# LFSS_1.0 register map
Vendor: Texas Instruments
Peripheral module from a debugger description file (folder mspm33c321x).
Registers are 32-bit, read-write, no defined reset value unless marked. A register's access mark holds for its fields unless they carry their own. Offsets are as the file gives them; lines under a group give offsets from that group; [hi:lo] are bit positions; {n}, {i} and the like mark numbered series; 'fields as' and 'values as' point back to an identical list; <NAME> marks a mode.

## LFSS
0x04 LFSS_PINCM group
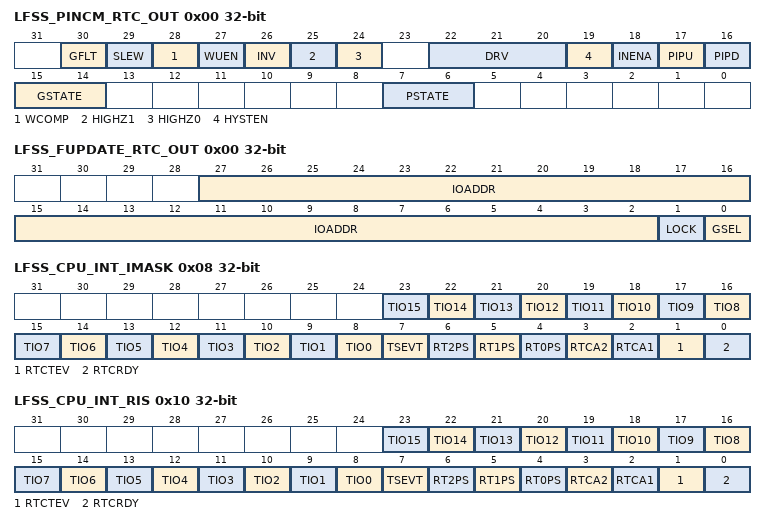
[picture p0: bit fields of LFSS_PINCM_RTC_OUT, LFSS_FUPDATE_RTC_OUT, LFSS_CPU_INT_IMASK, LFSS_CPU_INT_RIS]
  0x00 LFSS_PINCM_RTC_OUT — RTC_OUT
    [30] GFLT — Glitch Filter Enable
      0=DISABLE (No internal glitch filter); 1=ENABLE (Use internal glitch filter)
    [29] SLEW — Reserved Slew Rate Control
      0=DISABLE (No Slew Rate Control); 1=ENABLE (Use Slew Rate Control)
    [28] WCOMP — Wake up compare value
      0=MATCH_ZERO (Match 0 will wake); 1=MATCH_ONE (Match 1 will wake)
    [27] WUEN — Wake up enable
      0=NO_WAKEUP (Wake up not enabled); 1=WAKEUP (Wake up enabled)
    [26] INV — Invert digital input/output relative to peripheral/GPIO
      0=NO_CHNG (Input and output are non-inverted); 1=CHNG (Input and output are inverted)
    [25] HIGHZ1 — High-Z instead of high output
      0=DRV_HIGH (Pin can be driven high); 1=DRV_HIZ (Pin is tri-stated instead of driven high)
    [24] HIGHZ0 — High-Z instead of low output
      0=DRV_LOW (Pin can be driven low); 1=DRV_HIZ (Pin is tri-stated instead of driven low)
    [22:20] DRV — Drive strength options
      0=STRENGTH_0 (Lowest drive strength); {v}=STRENGTH_{v} (Drive strength {v+1}/8) (v=1..6); 7=STRENGTH_7 (Highest drive strength)
    [19] HYSTEN — Hysteresis enable
      0=DIS_HYST (No hysteresis); 1=EN_HYST (Hysteresis on)
    [18] INENA — Input enable
      0=INP_DISABLE (Inputs 0 to connected core); 1=INP_ENABLE (Inputs IO pad value to connected core)
    [17] PIPU — Pull up enable
      0=NO_PULL_UP; 1=PULL_UP
    [16] PIPD — Pull down enable
      0=NO_PULL_DOWN; 1=PULL_DOWN
    [15:14] GSTATE — GPIO Channel State
      0=UNASSIGNED (G-Channel is in Unassigned State); 1=HANDOVER (G-Channel is in Handover State); 2=CONC_NOT_LOCKED (G-Channel is in Connected State and not Locked (That is F field is allowed to change without going back through Unassigned state)); 3=CONC_LOCKED (G-Channel is in Connected State and Locked (That is F field is not allowed to change to a different non-Zero value until both G and P channels go to Unassigned))
    [7:6] PSTATE — Peripheral-Analog Channel State
      0=UNASSIGNED (P-Channel is in Unassigned State); 1=HANDOVER (P-Channel is in Handover State); 2=CONC_NOT_LOCKED (P-Channel is in Connected State and not Locked (That is F field is allowed to change without going back through Unassigned state)); 3=CONC_LOCKED (P-Channel is in Connected State and Locked (That is F field is not allowed to change to a different non-Zero value until both G and P channels go to Unassigned))
0x204 LFSS_FUPDATE group
  0x00 LFSS_FUPDATE_RTC_OUT — FUPDATE version of RTC_OUT
    [27:2] IOADDR — IO Address. This is the address that corresponds to the SOC address[27:2] of the module IP instance specific IO signal in the Full Write subregion of the pinmux subregion.
    [1] LOCK — Sets lock bit
      0=NOEFFECT (Writing this value has no effect); 1=LOCK (Set channel lock bit)
    [0] GSEL — GPIO channel Select 0: Select the P-Channel for the F update 1: Select the G-Channel for the F update
      0=PCHAN (Select the P-Channel for the F update); 1=GCHAN (Select the G-Channel for the F update)
0x400 LFSS_FSUB_0 — Subscriber Port 0
  [7:0] CHANID — 0 = disconnected. 1-255 = connected to channelID = CHANID.
    0=MNIMUM (0 is an allowed value, signifying that the event is unconnected); 0=UNCONNECTED (A value of 0 specifies that the event is not connected); 255=MAXIMUM (Consult your device datasheet as the actual allowed maximum may be less than 255.)
0x440 LFSS_FPUB_0 — Publisher Port 0
  [7:0] CHANID — 0 = disconnected. 1-15 = connected to channelID = CHANID.
    values as LFSS_FSUB_0.CHANID
0x480 LFSS_CPU_CONNECT_0 access not given — CPU Connect
0x1004 LFSS_CLKSEL ro — Clock Select for Ultra Low Power peripherals
  [1] LFCLK_SEL — Selects LFCLK as clock source if enabled
    0=DISABLE (LFCLK is disabled); 1=ENABLE (LFCLK is enabled)
0x1020 LFSS_CPU_INT group
  0x00 LFSS_CPU_INT_IIDX ro — Interrupt Index Register
    [7:0] STAT — Interrupt index status
      0=NO_INTR (No interrupt pending); 1=RTCRDY (RTC ready); 2=RTCTEV (RTC time event); 3=RTCA1 (RTC alarm 1); 4=RTCA2 (RTC alarm 2); 5=RT0PS (RTC prescale timer 0); 6=RT1PS (RTC prescale timer 1); 7=RT2PS (RTC prescale timer 2); 8=TSEVT (Time stamp event); {v}=TIO{v-9} (Tamper I/O {v-9} event) (v=9..24)
  0x08 LFSS_CPU_INT_IMASK — Interrupt mask
    [all] fields
      0=CLR (Clear Interrupt Mask); 1=SET (Set Interrrupt Mask)
    [n+8] TIO{n} (n=0..15) — Tamper I/O {n} event
    [7] TSEVT — Time stamp event
    [6] RT2PS — RTC prescale timer 2
    [5] RT1PS — RTC prescale timer 1
    [4] RT0PS — RTC prescale timer 0
    [3] RTCA2 — RTC alarm 2
    [2] RTCA1 — RTC alarm 1
    [1] RTCTEV — RTC time event
    [0] RTCRDY — RTC ready
  0x10 LFSS_CPU_INT_RIS — Raw interrupt status
    [all] fields
      0=CLR (Interrupt did not occur); 1=SET (Interrupt occurred)
    [n+8] TIO{n} (n=0..15) — Tamper I/O {n} event
    [7] TSEVT — Time stamp event
    [6] RT2PS — RTC prescale timer 2
    [5] RT1PS — RTC prescale timer 1
    [4] RT0PS — RTC prescale timer 0
    [3] RTCA2 — RTC alarm 2
    [2] RTCA1 — RTC alarm 1
    [1] RTCTEV — RTC time event
    [0] RTCRDY — RTC ready
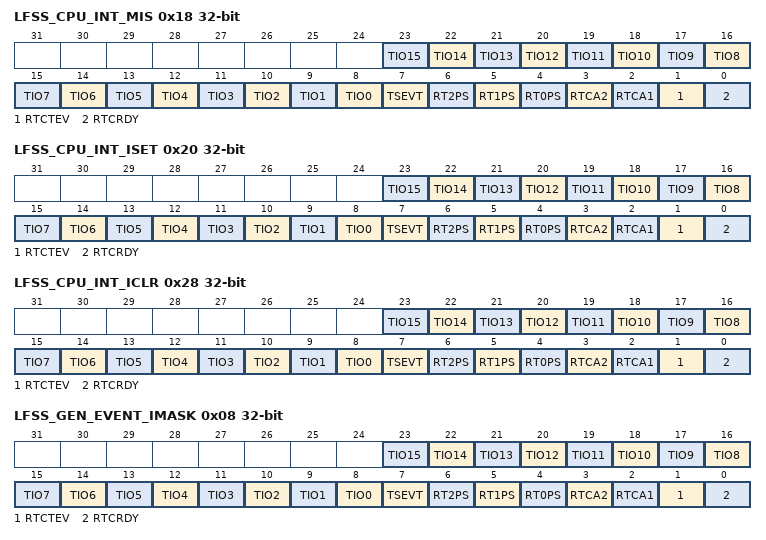
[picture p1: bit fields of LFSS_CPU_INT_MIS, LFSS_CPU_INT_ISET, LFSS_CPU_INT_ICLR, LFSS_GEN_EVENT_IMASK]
  0x18 LFSS_CPU_INT_MIS — Masked interrupt status
    [all] fields
      0=CLR (Interrupt did not occur or is masked out); 1=SET (Interrupt occurred)
    [n+8] TIO{n} (n=0..15) — Tamper I/O {n} event
    [7] TSEVT — Time stamp event
    [6] RT2PS — RTC prescale timer 2
    [5] RT1PS — RTC prescale timer 1
    [4] RT0PS — RTC prescale timer 0
    [3] RTCA2 — RTC alarm 2
    [2] RTCA1 — RTC alarm 1
    [1] RTCTEV — RTC time event
    [0] RTCRDY — RTC ready
  0x20 LFSS_CPU_INT_ISET — Interrupt set
    [all] fields
      0=NO_EFFECT (Writing 0 has no effect); 1=SET (Set interrupt)
    [n+8] TIO{n} (n=0..15) — Tamper I/O {n} event
    [7] TSEVT — Time stamp event
    [6] RT2PS — RTC prescale timer 2
    [5] RT1PS — RTC prescale timer 1
    [4] RT0PS — RTC prescale timer 0
    [3] RTCA2 — RTC alarm 2
    [2] RTCA1 — RTC alarm 1
    [1] RTCTEV — RTC time event
    [0] RTCRDY — RTC ready
  0x28 LFSS_CPU_INT_ICLR — Interrupt clear
    [all] fields
      0=NO_EFFECT (Writing 0 has no effect); 1=CLR (Clear interrupt)
    [n+8] TIO{n} (n=0..15) — Tamper I/O {n} event
    [7] TSEVT — Time stamp event
    [6] RT2PS — RTC prescale timer 2
    [5] RT1PS — RTC prescale timer 1
    [4] RT0PS — RTC prescale timer 0
    [3] RTCA2 — RTC alarm 2
    [2] RTCA1 — RTC alarm 1
    [1] RTCTEV — RTC time event
    [0] RTCRDY — RTC ready
0x1050 LFSS_GEN_EVENT group
  0x00 LFSS_GEN_EVENT_IIDX ro — Interrupt Index Register
    fields as LFSS_CPU_INT.LFSS_CPU_INT_IIDX
  0x08 LFSS_GEN_EVENT_IMASK — Interrupt mask
    fields as LFSS_CPU_INT.LFSS_CPU_INT_IMASK
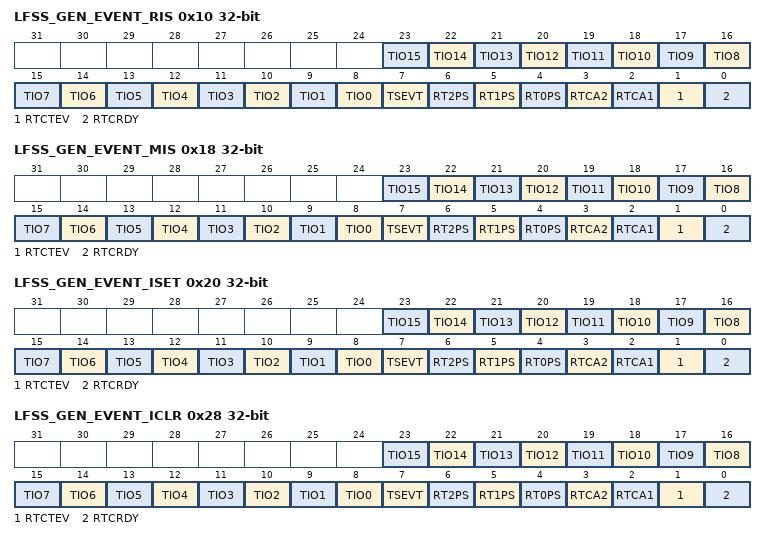
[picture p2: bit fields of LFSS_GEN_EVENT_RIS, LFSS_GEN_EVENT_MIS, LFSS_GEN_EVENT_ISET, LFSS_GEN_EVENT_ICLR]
  0x10 LFSS_GEN_EVENT_RIS — Raw interrupt status
    fields as LFSS_CPU_INT.LFSS_CPU_INT_RIS
  0x18 LFSS_GEN_EVENT_MIS — Masked interrupt status
    fields as LFSS_CPU_INT.LFSS_CPU_INT_MIS
  0x20 LFSS_GEN_EVENT_ISET — Interrupt set
    fields as LFSS_CPU_INT.LFSS_CPU_INT_ISET
  0x28 LFSS_GEN_EVENT_ICLR — Interrupt clear
    fields as LFSS_CPU_INT.LFSS_CPU_INT_ICLR
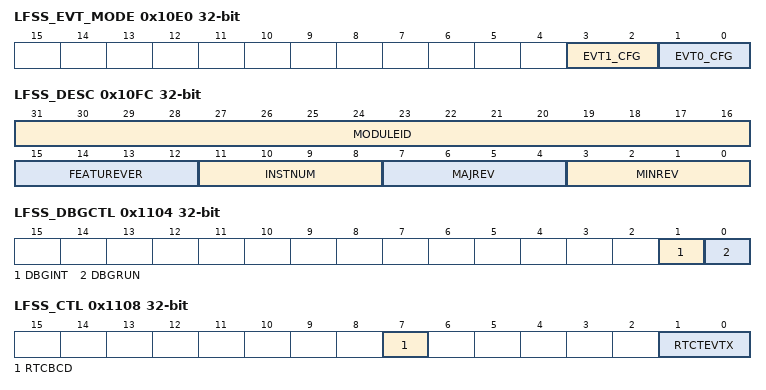
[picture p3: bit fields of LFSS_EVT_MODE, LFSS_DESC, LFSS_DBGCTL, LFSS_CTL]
0x10E0 LFSS_EVT_MODE ro — Event Mode
  [3:2] EVT1_CFG — Event line mode 1 select
    2=HARDWARE (The interrupt or event line is in hardware mode. The hardware (another module) clears automatically the associated RIS flag.)
  [1:0] EVT0_CFG — Event line mode 0 select
    1=SOFTWARE (The interrupt or event line is in software mode. The software ISR clears the associated RIS flag.)
0x10FC LFSS_DESC ro — LFSS Descriptor Register
  [31:16] MODULEID — Module identifier. This ID is unique for each module. 0x2911 = Module ID of the LFSS Module
    0=MINIMUM (Smallest value); 0xFFFF=MAXIMUM (Highest possible value)
  [15:12] FEATUREVER — Feature set of this module. Differentiates the complexity of the actually instantiated module if there are differences.
    0=MINIMUM (Smallest value); 15=MAXIMUM (Highest possible value)
  [11:8] INSTNUM — Instantiated version. Describes which instance of the module accessed.
    0=INST0 (This is the default, if there is only one instance - like for SSIM)
  [7:4] MAJREV — Major revision. This number holds the module revision and is incremented by the module developers. n = Major version (see device-specific data sheet)
    values as FEATUREVER
  [3:0] MINREV — Minor revision. This number holds the module revision and is incremented by the module developers. n = Minor module revision (see device-specific data sheet)
    values as FEATUREVER
0x1100 LFSS_CLKCTL — RTC Clock Control Register
  [31] MODCLKEN — This bit enables the supply of the 32kHz clock to the RTC. It will not power-up the 32kHz crystal oscillator this needs to be done in the Clock System Module.
    0=DISABLE (32kHz clock is not supplied to the RTC.); 1=ENABLE (32kHz clock is supplied to the RTC.)
0x1104 LFSS_DBGCTL — RTC Module Debug Control Register
  [1] DBGINT — Debug Interrupt Enable.
    0=OFF (Interrupts of the module will not be captured anymore if CPU is in debug state. Which means no update to the RTCRIS, RTCMISC and RTCIIDX register.); 1=ON (Interrupts are enabled in debug mode. Interrupt requests are signaled to the interrupt controller. If the flags are required by software (polling mode) the DGBINT bit need to be set to 1.)
  [0] DBGRUN — Debug Run.
    0=HALT (Counter is halted if CPU is in debug state.); 1=RUN (Continue to operate normally ignoring the debug state of the CPU.)
0x1108 LFSS_CTL — RTC Control Register
  [7] RTCBCD — Real-time clock BCD select. Selects BCD counting for real-time clock.
    0=BINARY (Binary code selected); 1=BCD (Binary coded decimal (BCD) code selected)
  [1:0] RTCTEVTX — Real-time clock time event 0x0 = Minute changed 0x1 = Hour changed 0x2 = Every day at midnight (00:00) 0x3 = Every day at noon (12:00)
    0=MINUTE (Generate RTC event every minute.); 1=HOUR (Generate RTC event every hour.); 2=MIDNIGHT (Generate RTC event at midnight.); 3=NOON (Generate RTC event at noon.)
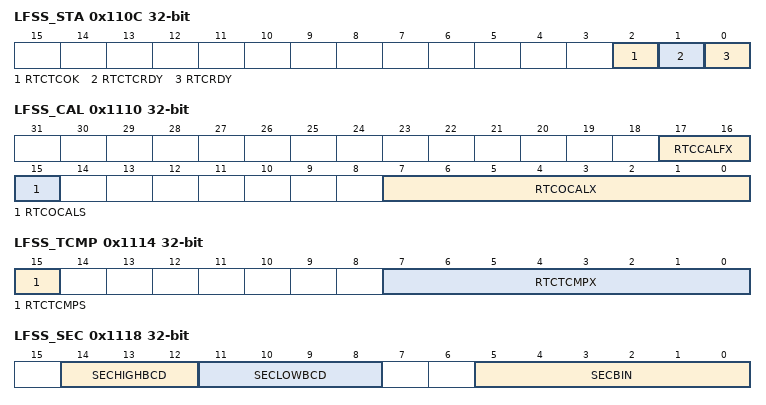
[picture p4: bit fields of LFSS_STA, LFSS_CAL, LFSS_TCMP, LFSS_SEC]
0x110C LFSS_STA ro — RTC Status Register
  [2] RTCTCOK — Real-time clock temperature compensation write OK. This is a read-only bit that indicates if the write to RTCTCMP is successful or not.
    0=NOT_OK (Write to RTCTCMPx is unsuccessful); 1=OK (Write to RTCTCMPx is successful)
  [1] RTCTCRDY — Real-time clock temperature compensation ready. This is a read only bit that indicates when the RTCTCMPx can be written. Write to RTCTCMPx should be avoided when RTCTCRDY is reset.
    0=NOT_READY (RTC temperature compensation in transition); 1=READY (RTC temperature compensation ready)
  [0] RTCRDY — Real-time clock ready. This bit indicates when the real-time clock time values are safe for reading.
    0=NOT_READY (RTC time values in transition); 1=READY (RTC time values safe for reading.)
0x1110 LFSS_CAL — RTC Clock Offset Calibration Register
  [17:16] RTCCALFX — Real-time clock calibration frequency. Selects frequency output to RTCCLK pin for calibration measurement. The corresponding port must be configured for the peripheral module function.
    0=F32KHZ (32 kHz); 1=F512HZ (512 Hz); 2=F256HZ (256 Hz); 3=F1HZ (1 Hz)
  [15] RTCOCALS — Real-time clock offset error calibration sign. This bit decides the sign of offset error calibration.
    0=DOWN (Down calibration. Frequency adjusted down.); 1=UP (Up calibration. Frequency adjusted up.)
  [7:0] RTCOCALX — Real-time clock offset error calibration. Each LSB represents approximately +1ppm (RTCOCALXS = 1) or -1ppm (RTCOCALXS = 0) adjustment in frequency. Maximum effective calibration value is +/-240ppm. Excess values written above +/-240ppm will be ignored by hardware.
    0=MINIMUM (Smallest value); 255=MAXIMUM (Highest possible value)
0x1114 LFSS_TCMP — RTC Temperature Compensation Register
  [15] RTCTCMPS — Real-time clock temperature compensation sign. This bit decides the sign of temperature compensation.
    values as LFSS_CAL.RTCOCALS
  [7:0] RTCTCMPX — Real-time clock temperature compensation. Value written into this register is used for temperature compensation of RTC. Each LSB represents approximately +1ppm (RTCTCMPS = 1) or -1ppm (RTCTCMPS = 0) adjustment in frequency. Maximum effective calibration value is +/-240ppm. Excess values written above +/-240ppm are ignored by hardware. Reading from RTCTCMP register at any time returns the cumulative value which is the signed addition of RTCOCALx and RTCTCMPX values, and the updated sign bit (RTCTCMPS) of the addition result.
    values as LFSS_CAL.RTCOCALX
0x1118 LFSS_SEC — RTC Seconds Register - Calendar Mode With Binary / BCD Format
  [14:12] SECHIGHBCD — Seconds BCD high digit (0 to 5). If RTCBCD=0 write to these bits will be ignored and read give the value 0.
    0=MINIMUM (Smallest value); 5=MAXIMUM (Highest possible value)
  [11:8] SECLOWBCD — Seconds BCD low digit (0 to 9). If RTCBCD=0 write to these bits will be ignored and read give the value 0.
    0=MINIMUM (Smallest value); 9=MAXIMUM (Highest possible value)
  [5:0] SECBIN — Seconds Binary (0 to 59). If RTCBCD=1 write to these bits will be ignored and read give the value 0.
    0=MINIMUM (Smallest value); 59=MAXIMUM (Highest possible value)
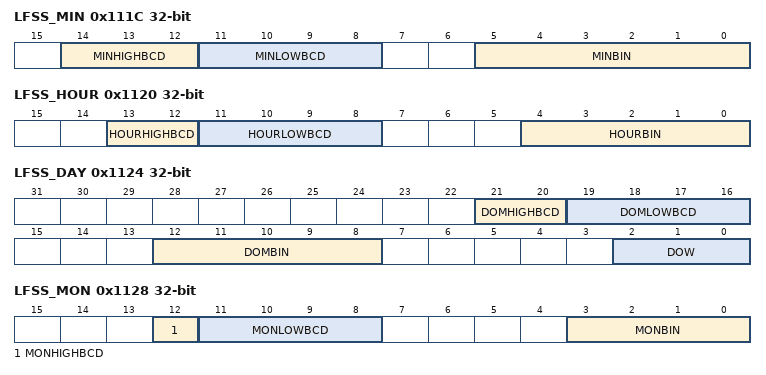
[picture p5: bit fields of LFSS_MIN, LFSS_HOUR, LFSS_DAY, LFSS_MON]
0x111C LFSS_MIN — RTC Minutes Register - Calendar Mode With Binary / BCD Format
  [14:12] MINHIGHBCD — Minutes BCD high digit (0 to 5). If RTCBCD=0 write to these bits will be ignored and read give the value 0.
    values as LFSS_SEC.SECHIGHBCD
  [11:8] MINLOWBCD — Minutes BCD low digit (0 to 9). If RTCBCD=0 write to these bits will be ignored and read give the value 0.
    values as LFSS_SEC.SECLOWBCD
  [5:0] MINBIN — Minutes Binary (0 to 59). If RTCBCD=1 write to these bits will be ignored and read give the value 0.
    values as LFSS_SEC.SECBIN
0x1120 LFSS_HOUR — RTC Hours Register - Calendar Mode With Binary / BCD Format
  [13:12] HOURHIGHBCD — Hours BCD high digit (0 to 2). If RTCBCD=0 write to these bits will be ignored and read give the value 0.
    0=MINIMUM (Smallest value); 2=MAXIMUM (Highest possible value)
  [11:8] HOURLOWBCD — Hours BCD low digit (0 to 9). If RTCBCD=0 write to these bits will be ignored and read give the value 0.
    values as LFSS_SEC.SECLOWBCD
  [4:0] HOURBIN — Hours Binary (0 to 23). If RTCBCD=1 write to these bits will be ignored and read give the value 0.
    0=MINIMUM (Smallest value); 23=MAXIMUM (Highest possible value)
0x1124 LFSS_DAY — RTC Day Of Week / Month Register - Calendar Mode With Binary / BCD Format
  [21:20] DOMHIGHBCD — Day of month BCD high digit (0 to 3). If RTCBCD=0 write to these bits will be ignored and read give the value 0.
    0=MINIMUM (Smallest value); 3=MAXIMUM (Highest possible value)
  [19:16] DOMLOWBCD — Day of month BCD low digit (0 to 9). If RTCBCD=0 write to these bits will be ignored and read give the value 0.
    values as LFSS_SEC.SECLOWBCD
  [12:8] DOMBIN — Day of month Binary (1 to 28, 29, 30, 31). If RTCBCD=1 write to these bits will be ignored and read give the value 0.
    0=MINIMUM (Smallest value); 31=MAXIMUM (Highest possible value)
  [2:0] DOW — Day of week (0 to 6). These bits are valid if RTCBCD=1 or RTCBCD=0.
    0=MINIMUM (Smallest value); 6=MAXIMUM (Highest possible value)
0x1128 LFSS_MON — RTC Month Register - Calendar Mode With Binary / BCD Format
  [12] MONHIGHBCD — Month BCD high digit (0 or 1). If RTCBCD=0 write to these bits will be ignored and read give the value 0.
    0=MINIMUM (Smallest value); 1=MAXIMUM (Highest possible value)
  [11:8] MONLOWBCD — Month BCD low digit (0 to 9). If RTCBCD=0 write to these bits will be ignored and read give the value 0.
    values as LFSS_SEC.SECLOWBCD
  [3:0] MONBIN — Month Binary (1 to 12). If RTCBCD=1 write to these bits will be ignored and read give the value 0.
    0=MINIMUM (Smallest value); 12=MAXIMUM (Highest possible value)
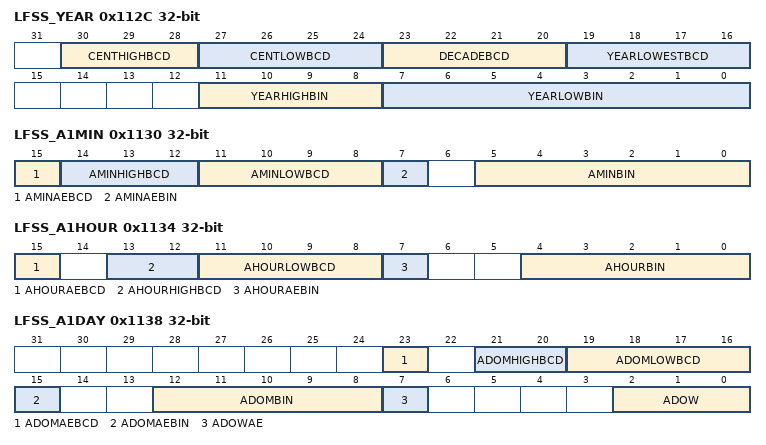
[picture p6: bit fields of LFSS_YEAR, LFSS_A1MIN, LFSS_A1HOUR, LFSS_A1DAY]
0x112C LFSS_YEAR — RTC Year Register - Calendar Mode With Binary / BCD Format
  [30:28] CENTHIGHBCD — Century BCD high digit (0 to 4). If RTCBCD=0 write to these bits will be ignored and read give the value 0.
    0=MINIMUM (Smallest value); 4=MAXIMUM (Highest possible value)
  [27:24] CENTLOWBCD — Century BCD low digit (0 to 9). If RTCBCD=0 write to these bits will be ignored and read give the value 0.
    values as LFSS_SEC.SECLOWBCD
  [23:20] DECADEBCD — Decade BCD (0 to 9). If RTCBCD=0 write to these bits will be ignored and read give the value 0.
    values as LFSS_SEC.SECLOWBCD
  [19:16] YEARLOWESTBCD — Year BCD lowest digit (0 to 9). If RTCBCD=0 write to these bits will be ignored and read give the value 0.
    values as LFSS_SEC.SECLOWBCD
  [11:8] YEARHIGHBIN — Year Binary high byte. Valid values for Year are 0 to 4095. If RTCBCD=1 write to these bits will be ignored and read give the value 0.
    values as LFSS_DESC.FEATUREVER
  [7:0] YEARLOWBIN — Year Binary low byte. Valid values for Year are 0 to 4095. If RTCBCD=1 write to these bits will be ignored and read give the value 0.
    values as LFSS_CAL.RTCOCALX
0x1130 LFSS_A1MIN — RTC Minute Alarm Register - Calendar Mode With Binary / BCD Format
  [15] AMINAEBCD — Alarm Minutes BCD enable. If RTCBCD=0 this bit is always 0. Write to this bit will be ignored. 0x0= Alarm disabled. 0x1= Alarm enabled.
    0=DISABLE (No alarm); 1=ENABLE (Alarm enabled)
  [14:12] AMINHIGHBCD — Alarm Minutes BCD high digit (0 to 5). If RTCBCD=0 write to these bits will be ignored and read give the value 0.
    values as LFSS_SEC.SECHIGHBCD
  [11:8] AMINLOWBCD — Alarm Minutes BCD low digit (0 to 9). If RTCBCD=0 write to these bits will be ignored and read give the value 0.
    values as LFSS_SEC.SECLOWBCD
  [7] AMINAEBIN — Alarm Minutes Binary enable. If RTCBCD=1 this bit is always 0. Write to this bit will be ignored. 0x0= Alarm disabled. 0x1= Alarm enabled.
    0=DISABLE (No alarm); 1=ENABLE (Alarm enabled)
  [5:0] AMINBIN — Alarm Minutes Binary (0 to 59). If RTCBCD=1 write to these bits will be ignored and read give the value 0.
    values as LFSS_SEC.SECBIN
0x1134 LFSS_A1HOUR — RTC Hours Alarm Register - Calendar Mode With Binary / BCD Format
  [15] AHOURAEBCD — Alarm Hours BCD enable. If RTCBCD=0 this bit is always 0. Write to this bit will be ignored. 0x0= Alarm disabled. 0x1= Alarm enabled.
    0=DISABLE (No alarm); 1=ENABLE (Alarm enabled)
  [13:12] AHOURHIGHBCD — Alarm Hours BCD high digit (0 to 2). If RTCBCD=0 write to these bits will be ignored and read give the value 0..
    values as LFSS_HOUR.HOURHIGHBCD
  [11:8] AHOURLOWBCD — Alarm Hours BCD low digit (0 to 9). If RTCBCD=0 write to these bits will be ignored and read give the value 0.
    values as LFSS_SEC.SECLOWBCD
  [7] AHOURAEBIN — Alarm Hours Binary enable. If RTCBCD=1 this bit is always 0. Write to this bit will be ignored. 0x0= Alarm disabled. 0x1= Alarm enabled.
    0=DISABLE (No alarm); 1=ENABLE (Alarm enabled)
  [4:0] AHOURBIN — Alarm Hours Binary (0 to 23). If RTCBCD=1 write to these bits will be ignored and read give the value 0.
    values as LFSS_HOUR.HOURBIN
0x1138 LFSS_A1DAY — RTC Alarm Day Of Week / Month Register - Calendar Mode With Binary / BCD Format
  [23] ADOMAEBCD — Alarm Day of month BCD enable. If RTCBCD=0 this bit is always 0. Write to this bit will be ignored. 0x0= Alarm disabled. 0x1= Alarm enabled.
    0=DISABLE (No alarm); 1=ENABLE (Alarm enabled)
  [21:20] ADOMHIGHBCD — Alarm Day of month BCD high digit (0 to 3). If RTCBCD=0 write to these bits will be ignored and read give the value 0.
    values as LFSS_DAY.DOMHIGHBCD
  [19:16] ADOMLOWBCD — Alarm Day of month BCD low digit (0 to 9). If RTCBCD=0 write to these bits will be ignored and read give the value 0.
    values as LFSS_SEC.SECLOWBCD
  [15] ADOMAEBIN — Alarm Day of month Binary enable. If RTCBCD=1 this bit is always 0. Write to this bit will be ignored. 0x0= Alarm disabled. 0x1= Alarm enabled.
    0=DISABLE (No alarm); 1=ENABLE (Alarm enabled)
  [12:8] ADOMBIN — Alarm Day of month Binary (1 to 28, 29, 30, 31) If RTCBCD=1 write to these bits will be ignored and read give the value 0.
    values as LFSS_DAY.DOMBIN
  [7] ADOWAE — Alarm Day of week enable. This bit are valid if RTCBCD=1 or RTCBCD=0.
    0=DISABLE (No alarm); 1=ENABLE (Alarm enabled)
  [2:0] ADOW — Alarm Day of week (0 to 6). These bits are valid if RTCBCD=1 or RTCBCD=0.
    values as LFSS_DAY.DOW
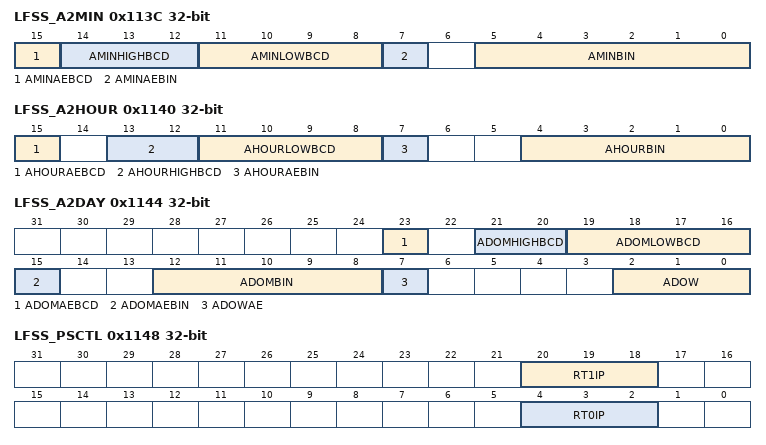
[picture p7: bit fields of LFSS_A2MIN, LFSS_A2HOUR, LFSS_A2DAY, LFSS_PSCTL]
0x113C LFSS_A2MIN — RTC Minute Alarm Register - Calendar Mode With Binary / BCD Format
  fields as LFSS_A1MIN
0x1140 LFSS_A2HOUR — RTC Hours Alarm Register - Calendar Mode With Binary / BCD Format
  fields as LFSS_A1HOUR
0x1144 LFSS_A2DAY — RTC Alarm Day Of Week / Month Register - Calendar Mode With Binary / BCD Format
  fields as LFSS_A1DAY
0x1148 LFSS_PSCTL — RTC Prescale Timer 0/1 Control Register
  [20:18] RT1IP — Prescale timer 1 interrupt interval
    0=INT15P6MS (Interval every 15.6 milisecond); 1=INT31P3MS (Interval every 31.3 milisecond); 2=INT62P5MS (Interval every 62.5 milisecond); 3=INT125MS (Interval every 125 milisecond); 4=INT250MS (Interval every 250 milisecond); 5=INT500MS (Interval every 500 milisecond); 6=INT1S (Interval every 1 second); 7=INT2S (Interval every 2 second)
  [4:2] RT0IP — Prescale timer 0 interrupt interval
    2=INT244US (Interval every 244 microsecond); 3=INT488US (Interval every 488 microsecond); 4=INT0P98MS (Interval every 0.98 milisecond); 5=INT1P95MS (Interval every 1.95 milisecond); 6=INT3P91MS (Interval every 3.91 milisecond); 7=INT7P81MS (Interval every 7.81 milisecond)
0x114C LFSS_EXTPSCTL — RTC Prescale Timer 2 Control Register
  [3:2] RT2PS — Prescale timer 2 interrupt interval
    0=INT4S (Interval every 4 second); 1=INT8S (Interval every 8 second); 2=INT16S (Interval every 16 second)
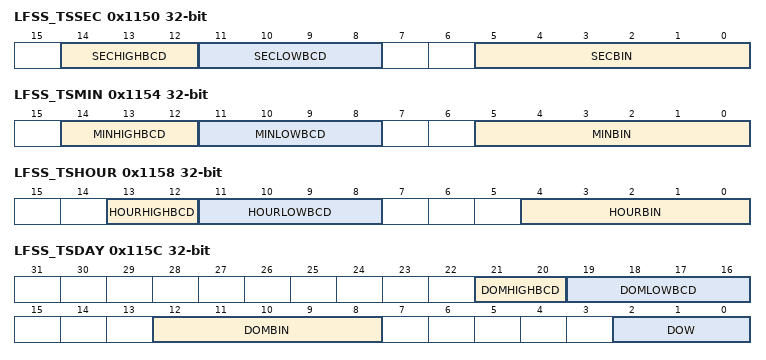
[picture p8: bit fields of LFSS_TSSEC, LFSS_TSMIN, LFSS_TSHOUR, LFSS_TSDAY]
0x1150 LFSS_TSSEC — Time Stamp Seconds Register - Calendar Mode With Binary / BCD Format
  [14:12] SECHIGHBCD — Time Stamp Seconds BCD high digit (0 to 5). If RTCBCD=0 write to these bits will be ignored and read give the value 0.
    values as LFSS_SEC.SECHIGHBCD
  [11:8] SECLOWBCD — Time Stamp Seconds BCD low digit (0 to 9). If RTCBCD=0 write to these bits will be ignored and read give the value 0.
    values as LFSS_SEC.SECLOWBCD
  [5:0] SECBIN — Time Stamp Second Binary (0 to 59). If RTCBCD=1 write to these bits will be ignored and read give the value 0.
    values as LFSS_SEC.SECBIN
0x1154 LFSS_TSMIN ro — Time Stamp Minutes Register - Calendar Mode With Binary / BCD Format
  [14:12] MINHIGHBCD — Time Stamp Minutes BCD high digit (0 to 5). If RTCBCD=0 write to these bits will be ignored and read give the value 0.
    values as LFSS_SEC.SECHIGHBCD
  [11:8] MINLOWBCD — Time Stamp Minutes BCD low digit (0 to 9). If RTCBCD=0 write to these bits will be ignored and read give the value 0.
    values as LFSS_SEC.SECLOWBCD
  [5:0] MINBIN — Time Stamp Minutes Binary (0 to 59). If RTCBCD=1 write to these bits will be ignored and read give the value 0.
    values as LFSS_SEC.SECBIN
0x1158 LFSS_TSHOUR ro — Time Stamp Hours Register - Calendar Mode With Binary / BCD Format
  [13:12] HOURHIGHBCD — Time Stamp Hours BCD high digit (0 to 2). If RTCBCD=0 write to these bits will be ignored and read give the value 0.
    values as LFSS_HOUR.HOURHIGHBCD
  [11:8] HOURLOWBCD — Time Stamp Hours BCD low digit (0 to 9). If RTCBCD=0 write to these bits will be ignored and read give the value 0.
    values as LFSS_SEC.SECLOWBCD
  [4:0] HOURBIN — Time Stamp Hours Binary (0 to 23). If RTCBCD=1 write to these bits will be ignored and read give the value 0.
    values as LFSS_HOUR.HOURBIN
0x115C LFSS_TSDAY ro — Time Stamp Day Of Week / MonthRegister - Calendar Mode With Binary / BCD Format
  [21:20] DOMHIGHBCD — Time Stamp Day of month BCD high digit (0 to 3). If RTCBCD=0 write to these bits will be ignored and read give the value 0.
    values as LFSS_DAY.DOMHIGHBCD
  [19:16] DOMLOWBCD — Time Stamp Day of month BCD low digit (0 to 9). If RTCBCD=0 write to these bits will be ignored and read give the value 0.
    values as LFSS_SEC.SECLOWBCD
  [12:8] DOMBIN — Time Stamp Day of month Binary (1 to 28, 29, 30, 31) If RTCBCD=1 write to these bits will be ignored and read give the value 0.
    values as LFSS_DAY.DOMBIN
  [2:0] DOW — Time Stamp Day of week (0 to 6). These bits are valid if RTCBCD=1 or RTCBCD=0.
    values as LFSS_DAY.DOW
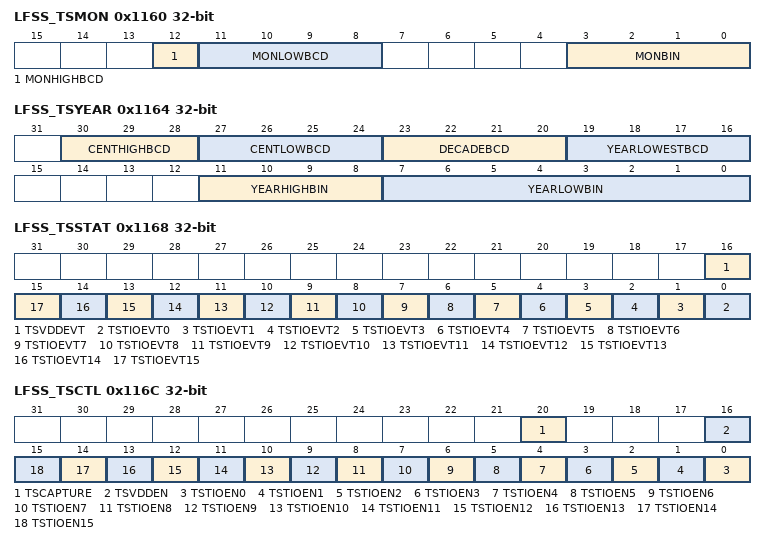
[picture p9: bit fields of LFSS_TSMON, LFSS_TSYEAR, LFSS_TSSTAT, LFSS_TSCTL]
0x1160 LFSS_TSMON ro — Time Stamp Month Register - Calendar Mode With Binary / BCD Format
  [12] MONHIGHBCD — Time Stamp Month BCD high digit (0 or 1). If RTCBCD=0 write to these bits will be ignored and read give the value 0.
    values as LFSS_MON.MONHIGHBCD
  [11:8] MONLOWBCD — Time Stamp Month BCD low digit (0 to 9). If RTCBCD=0 write to these bits will be ignored and read give the value 0.
    values as LFSS_SEC.SECLOWBCD
  [3:0] MONBIN — Time Stamp Month Binary (1 to 12). If RTCBCD=1 write to these bits will be ignored and read give the value 0.
    values as LFSS_MON.MONBIN
0x1164 LFSS_TSYEAR ro — Time Stamp Years Register - Calendar Mode With Binary / BCD Format
  [30:28] CENTHIGHBCD — Time Stamp Century BCD high digit (0 to 4). If RTCBCD=0 write to these bits will be ignored and read give the value 0.
    values as LFSS_YEAR.CENTHIGHBCD
  [27:24] CENTLOWBCD — Time Stamp Century BCD low digit (0 to 9). If RTCBCD=0 write to these bits will be ignored and read give the value 0.
    values as LFSS_SEC.SECLOWBCD
  [23:20] DECADEBCD — Time Stamp Decade BCD (0 to 9). If RTCBCD=0 write to these bits will be ignored and read give the value 0.
    values as LFSS_SEC.SECLOWBCD
  [19:16] YEARLOWESTBCD — Time Stamp Year BCD lowest digit (0 to 9). If RTCBCD=0 write to these bits will be ignored and read give the value 0.
    values as LFSS_SEC.SECLOWBCD
  [11:8] YEARHIGHBIN — Time Stamp Year Binary high byte. Valid values for Year are 0 to 4095. If RTCBCD=1 write to these bits will be ignored and read give the value 0.
    values as LFSS_DESC.FEATUREVER
  [7:0] YEARLOWBIN — Time Stamp Year Binary low byte. Valid values for Year are 0 to 4095. If RTCBCD=1 write to these bits will be ignored and read give the value 0.
    values as LFSS_CAL.RTCOCALX
0x1168 LFSS_TSSTAT ro — Time Stamp Status Register
  [all] fields
    0=CLR (no event detected); 1=SET (event detected)
  [16] TSVDDEVT — Loss of VDD caused time stamp event
  [n] TSTIOEVT{n} (n=0..15) — Tamper I/O {n} caused time stamp event
0x116C LFSS_TSCTL — Time Stamp Control Register
  [20] TSCAPTURE — Defines the capture method of the RTC timestamp when a time stamp event occurens.
    0=FIRST (Time stamp holds RTC capture at first occurrence of time stamp event.); 1=LAST (Time stamp holds RTC capture at last occurrence of time stamp event.)
  [16] TSVDDEN — Time Stamp by VDD Loss detection enable
    0=DISABLE (function disabled); 1=ENABLE (function enabled)
  [n] TSTIOEN{n} (n=0..15) — Time Stamp by Tamper I/O {n} enable
    0=DISABLE (function disabled); 1=ENABLE (function enabled)
0x1170 LFSS_TSCLR — Time Stamp Clear Register
  [0] CLR — Clear time stamp and status register.
    0=NO_EFFECT (Writing 0 has no effect); 1=CLR (clear time stamp event)
0x11F0 LFSS_LFSSRST — Low frequency sub-system reset request
  [0] VBATPOR — If set, the register bit will request a power on reset to the PMU of the LFSS.
    0=NO_EFFECT (Writing this value has no effect.); 1=SET (Request power on reset to the LFSS.)
0x11FC LFSS_RTCLOCK — Real time clock lock register
  [0] PROTECT — If set, the register bit will protect the CLKCTL, SEC, MIN, HOUR, DAY, MON, YEAR and LFSSRST from accidental writes.
    0=CLR (RTC counter is writable.); 1=SET (RTC counter is read only access.)
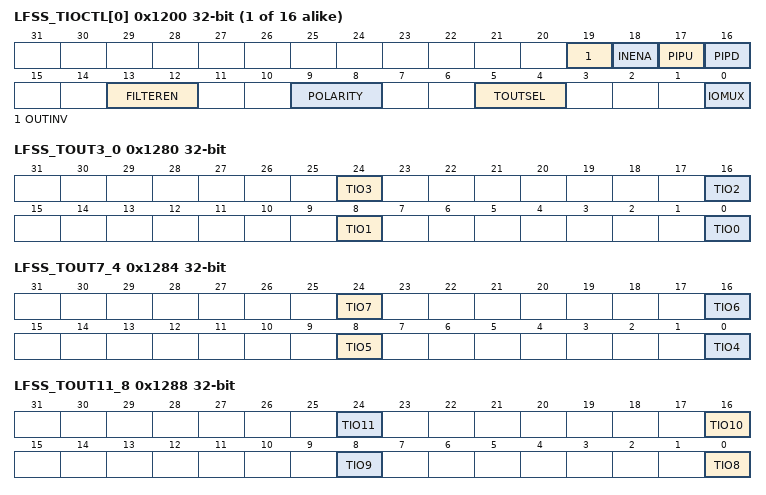
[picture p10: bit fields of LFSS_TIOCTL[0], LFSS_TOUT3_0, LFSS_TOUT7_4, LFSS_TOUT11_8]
{0x1200+4i} LFSS_TIOCTL[{i}] (i=0..15) — Tamper I/O Control Register
  [19] OUTINV — Output inversion enable
    0=DISBALE (The output inversion is disabled.); 1=ENABLE (The output inversion is enabled.)
  [18] INENA — input enable
    0=DISABLE (The input path is disabled.); 1=ENABLE (The input path is enabled.)
  [17] PIPU — pull up enable
    0=DISABLE (The pull-up function is disabled.); 1=ENABLE (The pull-up function is enabled.)
  [16] PIPD — pull down enable
    0=DISABLE (The pull-down function is disabled.); 1=ENABLE (The pull-down function is enabled.)
  [13:12] FILTEREN — Programmable counter length of digital glitch filter for TIO0
    0=NO_FLT (no filter on the tamper I/O beyond CDC synchronization sample); 1=FLT_1 (1 FLCLK minimum sample (30us)); 2=FLT_2 (3 LFCLK minimum sample (100us)); 3=FLT_3 (6 LFCLK minimum sample (200us))
  [9:8] POLARITY — Enables and configures edge detection polarity for TIO
    0=DISABLE (Edge detection disabled); 1=RISE (Detects rising edge of input event); 2=FALL (Detects falling edge of input event); 3=BOTH (Detects both rising and falling edge of input event)
  [5:4] TOUTSEL — Selects the source for TOUT control
    0=TOUT (The TOUT register is the source for TOUT); 1=LFCLKEXT (The LFCLK is the source for TOUT); 2=HEARTBEAT (The heart beat generatore is the source for TOUT); 3=TSEVTSTAT (The time stamp event status is the source for TOUT)
  [0] IOMUX — tamper I/O is controlled by SoC IOMUX module
    0=IOMUX (The tamper I/O is controlled by the IOMUX of the SoC and does allow assignment to a peripheral function. In the case the main supply (VDD) is lost, this I/O will go into a Hi-Z state.); 1=TAMPER (The tamper I/O is controlled by the TIOCTL register and stays functional during loss of the main supply (VDD).)
0x1280 LFSS_TOUT3_0 — Tamper Output 3 to 0
  [all] fields
    0=ZERO (Output is set to 0); 1=ONE (Output is set to 1)
  [24] TIO3 — This bit sets the value of the pin tamper I/O 3 (TIO3) when the output is enabled through TOE3 register.
  [16] TIO2 — This bit sets the value of the pin tamper I/O 2 (TIO0) when the output is enabled through TOE2 register.
  [8] TIO1 — This bit sets the value of the pin tamper I/O 1 (TIO1) when the output is enabled through TOE1 register.
  [0] TIO0 — This bit sets the value of the pin tamper I/O 0 (TIO0) when the output is enabled through TOE0 register.
0x1284 LFSS_TOUT7_4 — Tamper Output 7 to 4
  [all] fields
    0=ZERO (Output is set to 0); 1=ONE (Output is set to 1)
  [24] TIO7 — This bit sets the value of the pin tamper I/O 7 (TIO7) when the output is enabled through TOE7 register.
  [16] TIO6 — This bit sets the value of the pin tamper I/O 2 (TIO6) when the output is enabled through TOE6 register.
  [8] TIO5 — This bit sets the value of the pin tamper I/O 5 (TIO5) when the output is enabled through TOE5 register.
  [0] TIO4 — This bit sets the value of the pin tamper I/O 4 (TIO4) when the output is enabled through TOE4 register.
0x1288 LFSS_TOUT11_8 — Tamper Output 11 to 8
  [all] fields
    0=ZERO (Output is set to 0); 1=ONE (Output is set to 1)
  [8n-64] TIO{n} (n=8..11) — This bit sets the value of the pin tamper I/O {n} (TIO{n}) when the output is enabled through TOE{n} register.
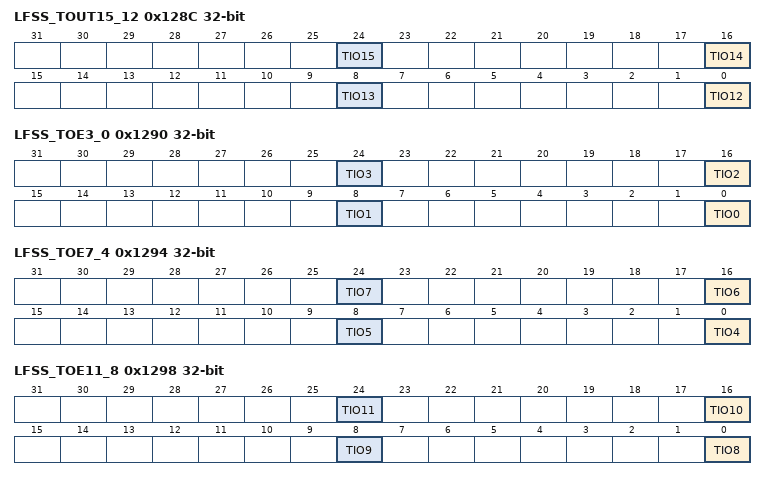
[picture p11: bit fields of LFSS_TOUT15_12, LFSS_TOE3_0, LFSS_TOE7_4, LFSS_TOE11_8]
0x128C LFSS_TOUT15_12 — Tamper Output 15 to 12
  [all] fields
    0=ZERO (Output is set to 0); 1=ONE (Output is set to 1)
  [8n-96] TIO{n} (n=12..15) — This bit sets the value of the pin tamper I/O {n} (TIO{n}) when the output is enabled through TOE{n} register.
0x1290 LFSS_TOE3_0 — Tamper Output Enable 3 to 0
  [all] fields
    0=DISABLE (output disabled); 1=ENABLE (output enabled)
  [8n] TIO{n} (n=0..3) — Enables data output for tamper I/O {n}
0x1294 LFSS_TOE7_4 — Tamper Output Enable 7 to 4
  [all] fields
    0=DISABLE (output disabled); 1=ENABLE (output enabled)
  [8n-32] TIO{n} (n=4..7) — Enables data output for tamper I/O {n}
0x1298 LFSS_TOE11_8 — Tamper Output Enable 7 to 4
  [all] fields
    0=DISABLE (output disabled); 1=ENABLE (output enabled)
  [8n-64] TIO{n} (n=8..11) — Enables data output for tamper I/O {n}
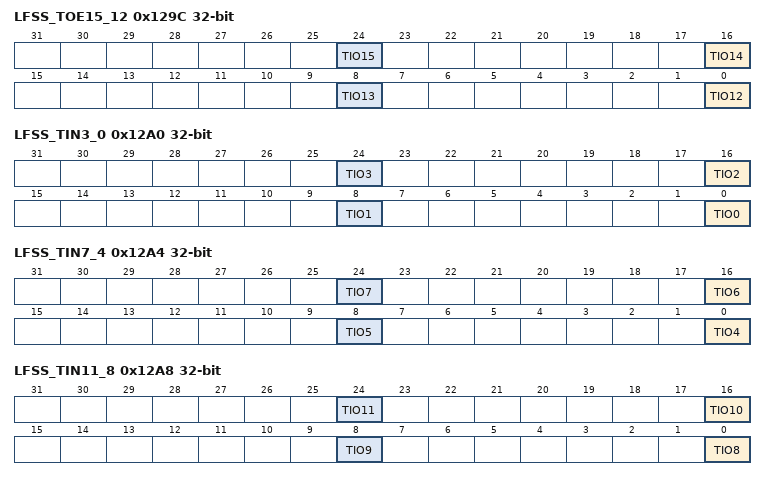
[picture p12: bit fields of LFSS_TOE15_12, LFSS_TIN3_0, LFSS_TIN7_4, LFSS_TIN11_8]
0x129C LFSS_TOE15_12 — Tamper Output Enable 7 to 4
  [all] fields
    0=DISABLE (output disabled); 1=ENABLE (output enabled)
  [8n-96] TIO{n} (n=12..15) — Enables data output for tamper I/O {n}
0x12A0 LFSS_TIN3_0 — Tamper Input Register
  [all] fields
    0=ZERO (Input value is 0); 1=ONE (Input value is 1)
  [8n] TIO{n} (n=0..3) — This bit reads the data input value of tamper I/O {n}.
0x12A4 LFSS_TIN7_4 — Tamper Input Register
  [all] fields
    0=ZERO (Input value is 0); 1=ONE (Input value is 1)
  [8n-32] TIO{n} (n=4..7) — This bit reads the data input value of tamper I/O {n}.
0x12A8 LFSS_TIN11_8 — Tamper Input Register
  [all] fields
    0=ZERO (Input value is 0); 1=ONE (Input value is 1)
  [8n-64] TIO{n} (n=8..11) — This bit reads the data input value of tamper I/O {n}.
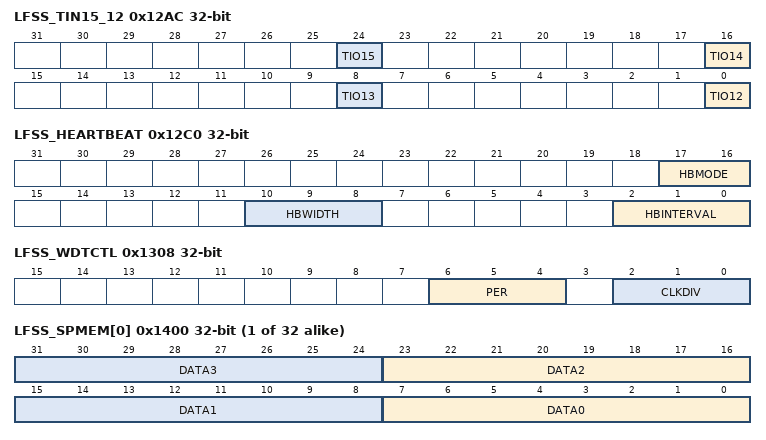
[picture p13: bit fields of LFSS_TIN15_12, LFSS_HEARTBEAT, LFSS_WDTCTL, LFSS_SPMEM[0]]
0x12AC LFSS_TIN15_12 — Tamper Input Register
  [all] fields
    0=ZERO (Input value is 0); 1=ONE (Input value is 1)
  [8n-96] TIO{n} (n=12..15) — This bit reads the data input value of tamper I/O {n}.
0x12C0 LFSS_HEARTBEAT — Heartbeat Register
  [17:16] HBMODE — Heart beat mode
    0=HB_DIS (Heart beat disabled); 1=HB_ALLWAYS (Heart beat allways enabled); 2=HB_TS (Heart beat enabled when time stamp event detected); 3=HB_VDDFAIL (Heart beat when VDD has fail condition)
  [10:8] HBWIDTH — Heart beat interval width
    0=HBPWDTH1 (Heart beat pulse width 1 msec); 1=HBPWDTH2 (Heart beat pulse width 2 msec); 2=HBPWDTH4 (Heart beat pulse width 4 msec); 3=HBPWDTH8 (Heart beat pulse width 8 msec); 4=HBPWDTH16 (Heart beat pulse width 16 msec); 5=HBPWDTH32 (Heart beat pulse width 32 msec); 6=HBPWDTH64 (Heart beat pulse width 64 msec); 7=HBPWDTH128 (Heart beat pulse width 128 msec)
  [2:0] HBINTERVAL — Heart beat interval
    0=HBINT0P125 (Heart beat interval 0.125 sec); 1=HBINT0P25 (Heart beat interval 0.25 sec); 2=HBINT0P5 (Heart beat interval 0.5 sec); 3=HBINT1 (Heart beat interval 1 sec); 4=HBINT2 (Heart beat interval 2 sec); 5=HBINT4 (Heart beat interval 4 sec); 6=HBINT8 (Heart beat interval 8 sec); 7=HBINT16 (Heart beat interval 16 sec)
0x12FC LFSS_TIOLOCK — Tamper I/O lock register
  [0] PROTECT — If set, the register bit will protect the TIOCTL and HEARTBEAT from accidental writes.
    0=CLR (Tamper I/O control is writable.); 1=SET (Tamper I/O control is read only access.)
0x1300 LFSS_WDTEN — Watchdog Timer Enable Register
  [0] ENABLE — Enable bit for the WDT.
    0=CLR (Disable WDT); 1=SET (Enable WDT)
0x1304 LFSS_WDTDBGCTL — Watchdog Timer Debug Control Register
  [0] FREE — Free run control
    0=STOP (The WDT freezes functionality while the CPU is Halted during debug and resumes when the CPU is active.); 1=RUN (The WDT ignores the state of the CPU Halted debug state.)
0x1308 LFSS_WDTCTL — Watchdog Timer Control Register
  [6:4] PER — Timer Period of the WDT. These bits select the total watchdog timer count.
    0=PER_EN_25 (Total timer count is 2^25); 1=PER_EN_21 (Total timer count is 2^21); 2=PER_EN_18 (Total timer count is 2^18); 3=PER_EN_15 (Total timer count is 2^15); 4=PER_EN_12 (Total timer count is 2^12 (default)); 5=PER_EN_10 (Total timer count is 2^10); 6=PER_EN_8 (Total timer count is 2^8); 7=PER_EN_6 (Total timer count is 2^6)
  [2:0] CLKDIV — Module Clock Divider, Divide the clock source by CLKDIV+1. Divider values from /1 to /8 are possible.
    0=MIN (Minimum value); 7=MAX (Maximum value)
0x130C LFSS_WDTCNTRST — Watchdog Timer Counter Reset Register
  [31:0] RESTART — Writing 03A7h to this register restarts the WDT Counter. Writing any other value causes a POR level reset. Read as 0x0h.
    0=MINIMUM (Minimum value); 0x3A7=VALUE (VALUE to restart the WDT counter); 0xFFFFFFFF=MAXIMUM (Maximum value)
0x1310 LFSS_WDTSTAT ro — Watchdog Timer Status Register
  [0] RUN — Watchdog running status flag.
    0=STOP (Watchdog counter stopped.); 1=RUN (Watchdog running.)
0x13FC LFSS_WDTLOCK — Watchdog timer lock register
  [0] PROTECT — If set, the register bit will protect the WDTEN and WDTCTL from accidental writes.
    0=CLR (Watchdog timer control is writable.); 1=SET (Watchdog timer control is read only access.)
{0x1400+4i} LFSS_SPMEM[{i}] (i=0..31) — Scratch Pad Memory Data Register
  [all] fields
    values as LFSS_CAL.RTCOCALX
  [8n+7:8n] DATA{n} (n=0..3) — memory data byte {n}
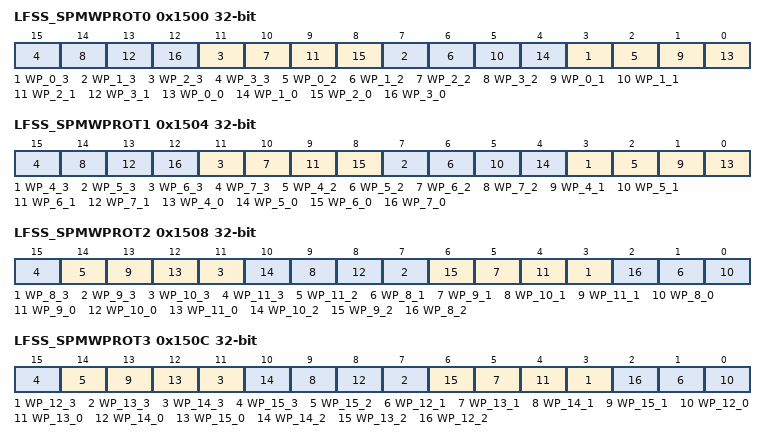
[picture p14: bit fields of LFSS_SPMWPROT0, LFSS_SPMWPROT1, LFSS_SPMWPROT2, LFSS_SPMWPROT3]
0x1500 LFSS_SPMWPROT0 — Scratch Pad Memory Write Protect Register 0
  [all] fields
    0=READWRITE (SPMEM is read and write access); 1=READONLY (SPMEM is read only access)
  [4n+3] WP_{n}_3 (n=0..3) — write protect SPMEM{n} - DATA3
  [4n+2] WP_{n}_2 (n=0..3) — write protect SPMEM{n} - DATA2
  [4n+1] WP_{n}_1 (n=0..3) — write protect SPMEM{n} - DATA1
  [4n] WP_{n}_0 (n=0..3) — write protect SPMEM{n} - DATA0
0x1504 LFSS_SPMWPROT1 — Scratch Pad Memory Write Protect Register 1
  [all] fields
    values as the fields of LFSS_SPMWPROT0
  [4n-13] WP_{n}_3 (n=4..7) — write protect SPMEM{n} - DATA3
  [4n-14] WP_{n}_2 (n=4..7) — write protect SPMEM{n} - DATA2
  [4n-15] WP_{n}_1 (n=4..7) — write protect SPMEM{n} - DATA1
  [4n-16] WP_{n}_0 (n=4..7) — write protect SPMEM{n} - DATA0
0x1508 LFSS_SPMWPROT2 — Scratch Pad Memory Write Protect Register 2
  [all] fields
    values as the fields of LFSS_SPMWPROT0
  [4n-29] WP_{n}_3 (n=8..11) — write protect SPMEM{n} - DATA3
  [14] WP_11_2 — write protect SPMEM11 - DATA2
  [4n-31] WP_{n}_1 (n=8..11) — write protect SPMEM{n} - DATA1
  [4n-32] WP_{n}_0 (n=8..11) — write protect SPMEM{n} - DATA0
  [10] WP_10_2 — write protect SPMEM610- DATA2
  [6] WP_9_2 — write protect SPMEM9 - DATA2
  [2] WP_8_2 — write protect SPMEM8 - DATA2
0x150C LFSS_SPMWPROT3 — Scratch Pad Memory Write Protect Register 3
  [all] fields
    values as the fields of LFSS_SPMWPROT0
  [4n-45] WP_{n}_3 (n=12..15) — write protect SPMEM{n} - DATA3
  [14] WP_15_2 — write protect SPMEM15 - DATA2
  [4n-47] WP_{n}_1 (n=12..15) — write protect SPMEM{n} - DATA1
  [4n-48] WP_{n}_0 (n=12..15) — write protect SPMEM{n} - DATA0
  [10] WP_14_2 — write protect SPMEM14- DATA2
  [6] WP_13_2 — write protect SPMEM13 - DATA2
  [2] WP_12_2 — write protect SPMEM12 - DATA2
0x1510 LFSS_SPMWPROT4 — Scratch Pad Memory Write Protect Register 4
  [all] fields
    values as the fields of LFSS_SPMWPROT0
  [4n-61] WP_{n}_3 (n=16..19) — write protect SPMEM{n} - DATA3
  [14] WP_19_2 — write protect SPMEM19 - DATA2
  [4n-63] WP_{n}_1 (n=16..19) — write protect SPMEM{n} - DATA1
  [4n-64] WP_{n}_0 (n=16..19) — write protect SPMEM{n} - DATA0
  [10] WP_18_2 — write protect SPMEM18- DATA2
  [6] WP_17_2 — write protect SPMEM17 - DATA2
  [2] WP_16_2 — write protect SPMEM16 - DATA2
0x1514 LFSS_SPMWPROT5 — Scratch Pad Memory Write Protect Register 5
  [all] fields
    values as the fields of LFSS_SPMWPROT0
  [4n-77] WP_{n}_3 (n=20..23) — write protect SPMEM{n} - DATA3
  [14] WP_23_2 — write protect SPMEM23 - DATA2
  [4n-79] WP_{n}_1 (n=20..23) — write protect SPMEM{n} - DATA1
  [4n-80] WP_{n}_0 (n=20..23) — write protect SPMEM{n} - DATA0
  [10] WP_22_2 — write protect SPMEM22- DATA2
  [6] WP_21_2 — write protect SPMEM21 - DATA2
  [2] WP_20_2 — write protect SPMEM20 - DATA2
0x1518 LFSS_SPMWPROT6 — Scratch Pad Memory Write Protect Register 6
  [all] fields
    values as the fields of LFSS_SPMWPROT0
  [4n-93] WP_{n}_3 (n=24..27) — write protect SPMEM{n} - DATA3
  [14] WP_27_2 — write protect SPMEM27 - DATA2
  [4n-95] WP_{n}_1 (n=24..27) — write protect SPMEM{n} - DATA1
  [4n-96] WP_{n}_0 (n=24..27) — write protect SPMEM{n} - DATA0
  [10] WP_26_2 — write protect SPMEM26- DATA2
  [6] WP_25_2 — write protect SPMEM25 - DATA2
  [2] WP_24_2 — write protect SPMEM24 - DATA2
0x151C LFSS_SPMWPROT7 — Scratch Pad Memory Write Protect Register 7
  [all] fields
    values as the fields of LFSS_SPMWPROT0
  [4n-109] WP_{n}_3 (n=28..31) — write protect SPMEM{n} - DATA3
  [14] WP_31_2 — write protect SPMEM31 - DATA2
  [4n-111] WP_{n}_1 (n=28..31) — write protect SPMEM{n} - DATA1
  [4n-112] WP_{n}_0 (n=28..31) — write protect SPMEM{n} - DATA0
  [10] WP_30_2 — write protect SPMEM30- DATA2
  [6] WP_29_2 — write protect SPMEM29 - DATA2
  [2] WP_28_2 — write protect SPMEM28 - DATA2
0x1540 LFSS_SPMTERASE0 — Scratch Pad Memory Tamper Erase Register 0
  [all] fields
    0=DISABLE (SPMEM is unmodified during tamper event); 1=ENABLE (SPMEM will be erased with tamper event)
  [4n+3] TE_{n}_3 (n=0..3) — tamper erase enable SPMEM{n} - DATA3
  [4n+2] TE_{n}_2 (n=0..3) — tamper erase enable SPMEM{n} - DATA2
  [4n+1] TE_{n}_1 (n=0..3) — tamper erase enable SPMEM{n} - DATA1
  [4n] TE_{n}_0 (n=0..3) — tamper erase enable SPMEM{n} - DATA0
0x1544 LFSS_SPMTERASE1 — Scratch Pad Memory Tamper Erase Register 1
  [all] fields
    values as the fields of LFSS_SPMTERASE0
  [4n-13] TE_{n}_3 (n=4..7) — tamper erase enable SPMEM{n} - DATA3
  [4n-14] TE_{n}_2 (n=4..7) — tamper erase enable SPMEM{n} - DATA2
  [4n-15] TE_{n}_1 (n=4..7) — tamper erase enable SPMEM{n} - DATA1
  [4n-16] TE_{n}_0 (n=4..7) — tamper erase enable SPMEM{n} - DATA0
0x1548 LFSS_SPMTERASE2 — Scratch Pad Memory Tamper Erase Register 2
  [all] fields
    values as the fields of LFSS_SPMTERASE0
  [4n-29] TE_{n}_3 (n=8..11) — tamper erase enable SPMEM{n} - DATA3
  [4n-30] TE_{n}_2 (n=8..11) — tamper erase enable SPMEM{n} - DATA2
  [4n-31] TE_{n}_1 (n=8..11) — tamper erase enable SPMEM{n} - DATA1
  [4n-32] TE_{n}_0 (n=8..11) — tamper erase enable SPMEM{n} - DATA0
0x154C LFSS_SPMTERASE3 — Scratch Pad Memory Tamper Erase Register 3
  [all] fields
    values as the fields of LFSS_SPMTERASE0
  [4n-45] TE_{n}_3 (n=12..15) — tamper erase enable SPMEM{n} - DATA3
  [4n-46] TE_{n}_2 (n=12..15) — tamper erase enable SPMEM{n} - DATA2
  [4n-47] TE_{n}_1 (n=12..15) — tamper erase enable SPMEM{n} - DATA1
  [4n-48] TE_{n}_0 (n=12..15) — tamper erase enable SPMEM{n} - DATA0
0x1550 LFSS_SPMTERASE4 — Scratch Pad Memory Tamper Erase Register 4
  [all] fields
    values as the fields of LFSS_SPMTERASE0
  [4n-61] TE_{n}_3 (n=16..19) — tamper erase enable SPMEM{n} - DATA3
  [4n-62] TE_{n}_2 (n=16..19) — tamper erase enable SPMEM{n} - DATA2
  [4n-63] TE_{n}_1 (n=16..19) — tamper erase enable SPMEM{n} - DATA1
  [4n-64] TE_{n}_0 (n=16..19) — tamper erase enable SPMEM{n} - DATA0
0x1554 LFSS_SPMTERASE5 — Scratch Pad Memory Tamper Erase Register 5
  [all] fields
    values as the fields of LFSS_SPMTERASE0
  [4n-77] TE_{n}_3 (n=20..23) — tamper erase enable SPMEM{n} - DATA3
  [4n-78] TE_{n}_2 (n=20..23) — tamper erase enable SPMEM{n} - DATA2
  [4n-79] TE_{n}_1 (n=20..23) — tamper erase enable SPMEM{n} - DATA1
  [4n-80] TE_{n}_0 (n=20..23) — tamper erase enable SPMEM{n} - DATA0
0x1558 LFSS_SPMTERASE6 — Scratch Pad Memory Tamper Erase Register 6
  [all] fields
    values as the fields of LFSS_SPMTERASE0
  [4n-93] TE_{n}_3 (n=24..27) — tamper erase enable SPMEM{n} - DATA3
  [4n-94] TE_{n}_2 (n=24..27) — tamper erase enable SPMEM{n} - DATA2
  [4n-95] TE_{n}_1 (n=24..27) — tamper erase enable SPMEM{n} - DATA1
  [4n-96] TE_{n}_0 (n=24..27) — tamper erase enable SPMEM{n} - DATA0
0x155C LFSS_SPMTERASE7 — Scratch Pad Memory Tamper Erase Register 7
  [all] fields
    values as the fields of LFSS_SPMTERASE0
  [4n-109] TE_{n}_3 (n=28..31) — tamper erase enable SPMEM{n} - DATA3
  [4n-110] TE_{n}_2 (n=28..31) — tamper erase enable SPMEM{n} - DATA2
  [4n-111] TE_{n}_1 (n=28..31) — tamper erase enable SPMEM{n} - DATA1
  [4n-112] TE_{n}_0 (n=28..31) — tamper erase enable SPMEM{n} - DATA0
